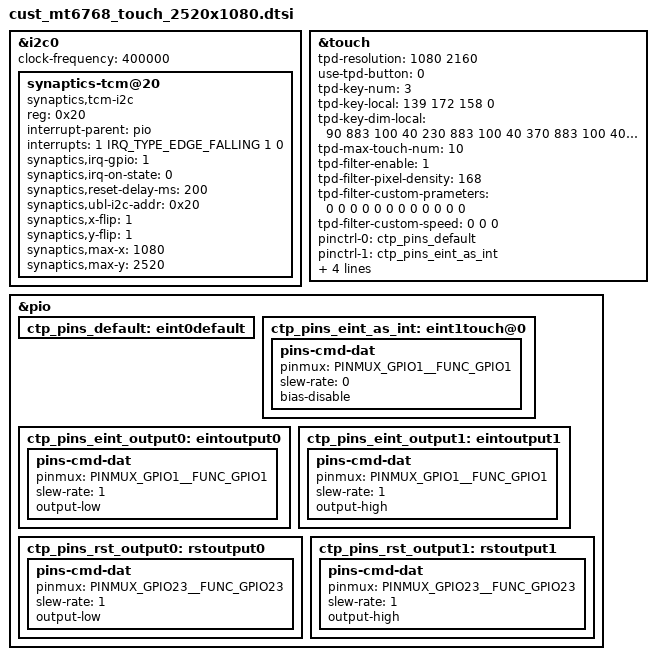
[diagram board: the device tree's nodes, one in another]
// SPDX-License-Identifier: GPL-2.0
/*
 * Copyright (c) 2019 MediaTek Inc.
 */

/* TOUCH start */
&i2c0 {
	clock-frequency = <400000>;
	synaptics-tcm@20 {
		compatible = "synaptics,tcm-i2c";
		reg = <0x20>;
		interrupt-parent = <&pio>;
		interrupts = <1 IRQ_TYPE_EDGE_FALLING 1 0>;
		synaptics,irq-gpio = <1>;
		synaptics,irq-on-state = <0>;
		synaptics,reset-delay-ms =<200>;
		synaptics,ubl-i2c-addr =<0x20>;
		synaptics,x-flip =<1>;
		synaptics,y-flip =<1>;
		synaptics,max-x =<1080>;
		synaptics,max-y =<2520>;
		status = "okay";
	};
};

&touch {
	tpd-resolution = <1080 2160>;
	use-tpd-button = <0>;
	tpd-key-num = <3>;
	tpd-key-local= <139 172 158 0>;
	tpd-key-dim-local = <90 883 100 40 230
				883 100 40 370 883 100 40 0 0 0 0>;
	tpd-max-touch-num = <10>;
	tpd-filter-enable = <1>;
	tpd-filter-pixel-density = <168>;
	tpd-filter-custom-prameters = <0 0 0 0 0 0 0 0 0 0 0 0>;
	tpd-filter-custom-speed = <0 0 0>;
	pinctrl-names = "default", "state_eint_as_int",
		"state_eint_output0", "state_eint_output1",
		"state_rst_output0", "state_rst_output1";
	pinctrl-0 = <&ctp_pins_default>;
	pinctrl-1 = <&ctp_pins_eint_as_int>;
	pinctrl-2 = <&ctp_pins_eint_output0>;
	pinctrl-3 = <&ctp_pins_eint_output1>;
	pinctrl-4 = <&ctp_pins_rst_output0>;
	pinctrl-5 = <&ctp_pins_rst_output1>;
	status = "okay";
};
&pio {
	ctp_pins_default: eint0default {
	};
	ctp_pins_eint_as_int: eint1touch@0 {
		pins-cmd-dat {
			pinmux = <PINMUX_GPIO1__FUNC_GPIO1>;
			slew-rate = <0>;
			bias-disable;
		};
	};
	ctp_pins_eint_output0: eintoutput0 {
		pins-cmd-dat {
			pinmux = <PINMUX_GPIO1__FUNC_GPIO1>;
			slew-rate = <1>;
			output-low;
		};
	};
	ctp_pins_eint_output1: eintoutput1 {
		pins-cmd-dat {
			pinmux = <PINMUX_GPIO1__FUNC_GPIO1>;
			slew-rate = <1>;
			output-high;
	};
	};
	ctp_pins_rst_output0: rstoutput0 {
		pins-cmd-dat {
			pinmux = <PINMUX_GPIO23__FUNC_GPIO23>;
			slew-rate = <1>;
			output-low;
		};
	};
	ctp_pins_rst_output1: rstoutput1 {
		pins-cmd-dat {
			pinmux = <PINMUX_GPIO23__FUNC_GPIO23>;
			slew-rate = <1>;
			output-high;
		};
	};
};
/* TOUCH end */
